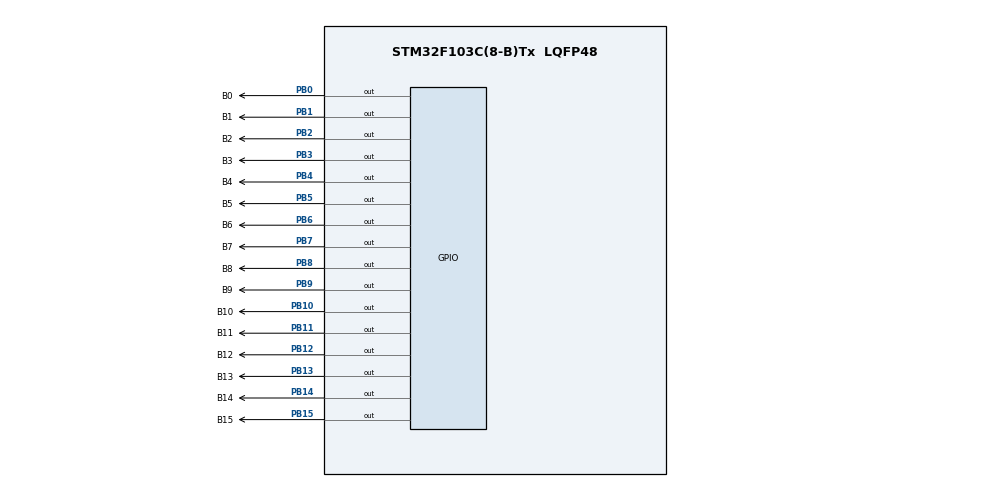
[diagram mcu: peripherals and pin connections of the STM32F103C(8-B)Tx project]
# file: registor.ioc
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Mcu.Family=STM32F1
Mcu.Name=STM32F103C(8-B)Tx
Mcu.Package=LQFP48
NVIC.PriorityGroup=NVIC_PRIORITYGROUP_4
PB0.GPIO_Label=B0
PB0.Signal=GPIO_Output
PB1.GPIO_Label=B1
PB1.Signal=GPIO_Output
PB10.GPIO_Label=B10
PB10.Signal=GPIO_Output
PB11.GPIO_Label=B11
PB11.Signal=GPIO_Output
PB12.GPIO_Label=B12
PB12.Signal=GPIO_Output
PB13.GPIO_Label=B13
PB13.Signal=GPIO_Output
PB14.GPIO_Label=B14
PB14.Signal=GPIO_Output
PB15.GPIO_Label=B15
PB15.Signal=GPIO_Output
PB2.GPIO_Label=B2
PB2.Signal=GPIO_Output
PB3.GPIO_Label=B3
PB3.Signal=GPIO_Output
PB4.GPIO_Label=B4
PB4.Signal=GPIO_Output
PB5.GPIO_Label=B5
PB5.Signal=GPIO_Output
PB6.GPIO_Label=B6
PB6.Signal=GPIO_Output
PB7.GPIO_Label=B7
PB7.Signal=GPIO_Output
PB8.GPIO_Label=B8
PB8.Signal=GPIO_Output
PB9.GPIO_Label=B9
PB9.Signal=GPIO_Output
PD0-OSC_IN.Mode=HSE-External-Oscillator
PD0-OSC_IN.Signal=RCC_OSC_IN
PD1-OSC_OUT.Mode=HSE-External-Oscillator
PD1-OSC_OUT.Signal=RCC_OSC_OUT
ProjectManager.HeapSize=0x200
ProjectManager.StackSize=0x400
ProjectManager.TargetToolchain=STM32CubeIDE
RCC.APB1Freq_Value=8000000
RCC.APB2Freq_Value=8000000
VP_SYS_VS_ND.Mode=No_Debug
board=custom

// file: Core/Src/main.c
/* USER CODE BEGIN Header */
/**
  ******************************************************************************
  * @file           : main.c
  * @brief          : Main program body
  ******************************************************************************
  * @attention
  *
  * Copyright (c) 2023 STMicroelectronics.
  * All rights reserved.
  *
  * This software is licensed under terms that can be found in the LICENSE file
  * in the root directory of this software component.
  * If no LICENSE file comes with this software, it is provided AS-IS.
  *
  ******************************************************************************
  */
/* USER CODE END Header */
#include "main.h"

void SystemClock_Config(void);
static void MX_GPIO_Init(void);

/* USER CODE BEGIN 0 */
uint32_t a;

/* USER CODE END 0 */

int main(void)
{

  /* MCU Configuration--------------------------------------------------------*/

  /* Reset of all peripherals, Initializes the Flash interface and the Systick. */
  HAL_Init();

  /* Configure the system clock */
  SystemClock_Config();

  /* Initialize all configured peripherals */
  MX_GPIO_Init();
  /* USER CODE BEGIN 2 */

   //ACTIVO EL CONTADOR PARA DEBBUGER
      CoreDebug->DEMCR |= CoreDebug_DEMCR_TRCENA_Msk;
       DWT->CTRL |= DWT_CTRL_CYCCNTENA_Msk;

  /* USER CODE END 2 */

  /* Infinite loop */
  /* USER CODE BEGIN WHILE */

   GPIOB->ODR=0x0f0f;
   HAL_Delay(1000);

   while (1)
  {  // encender un led

       DWT->CYCCNT=0;  //LIMPI EL CONTADOR
     //  HAL_GPIO_TogglePin(B5_GPIO_Port, B5_Pin);// 46 cicLo
      // HAL_Delay(200);

/*
       //afectando otros bit
         DWT->CYCCNT=0;  //LIMPI EL CONTADOR
         GPIOB->ODR=1<<5; // 4 CICLO
         HAL_Delay(100);
         DWT->CYCCNT=0;  //LIMPI EL CONTADOR
         B5_GPIO_Port->ODR=0;    //4 CICLO
         HAL_Delay(100);
*/

/*
       //afectando otros bit
       DWT->CYCCNT=0;  //LIMPI EL CONTADOR
       B5_GPIO_Port->ODR=B5_Pin; // 4 CICLO
       HAL_Delay(100);
       B5_GPIO_Port->ODR=0;    //4 CICLO
       HAL_Delay(100);
*/

/*
    //sin afectar otro bit usando xor
      DWT->CYCCNT=0;
       GPIOB->ODR= GPIOB->ODR ^ B5_Pin; // 11 CICLO
      HAL_Delay(200);
    // GPIOB->ODR^=B5_Pin;  // 11 CICLOS
*/

/*
   	 //SIN AFECTAR otro bit forma atomica

        DWT->CYCCNT=0;  //LIMPI EL CONTADOR
          GPIOB->BSRR=B5_Pin;
           HAL_Delay(100);
           DWT->CYCCNT=0;  //LIMPI EL CONTADOR
           B5_GPIO_Port->BRR=B5_Pin;
           HAL_Delay(100);
*/

    /*   // FORMA ATOMICA USANDO SOLO REGISTRO BSRR
	      GPIOB->BSRR=B5_Pin;//coloca 1
	      //GPIOB->BSRR=1<<5;
		  HAL_Delay(100);
		  GPIOB->BSRR=B5_Pin<<16;//COLOCA EL CERO
		  //  GPIOB->BSRR=1<<(16+5);//  si va a coloca cero lo desplaza 16 veces + el bit deseasdo
		  HAL_Delay(100);
*/

//  COLOCAR UN BIT ESPECIFICO EN UNO  (15)

		  //MODO ATOMICO
	 // B15_GPIO_Port->BSRR=B15_Pin;

		   //NO ATOMICO

		  //B15_GPIO_Port->ODR |=B15_Pin;
	//	  GPIOB->ODR |=1<<15;

         //colocar un bit en cero  (11)
		   //MODO ATOMICO
//			B11_GPIO_Port->BRR=B11_Pin;

		  //no atpmica
		//   GPIOB->ODR &=~(1<<11);

		  //INVERTIR UN BIT (14)
		  //GPIOB->ODR ^=1<<14;

       // CARGA DE UN DATO FORMA ATOMICA
          a=0B10101010101010101;
          DWT->CYCCNT=0;  //LIMPI EL CONTADOR
          GPIOB->BSRR=a|(~a<<16);///14 ciclos cargar un dato de forma atomica
         // DWT->CYCCNT=0;  //LIMPI EL CONTADOR

    /* USER CODE END WHILE */

  }
}

void SystemClock_Config(void)
{
  RCC_OscInitTypeDef RCC_OscInitStruct = {0};
  RCC_ClkInitTypeDef RCC_ClkInitStruct = {0};

  /** Initializes the RCC Oscillators according to the specified parameters
  * in the RCC_OscInitTypeDef structure.
  */
  RCC_OscInitStruct.OscillatorType = RCC_OSCILLATORTYPE_HSI;
  RCC_OscInitStruct.HSIState = RCC_HSI_ON;
  RCC_OscInitStruct.HSICalibrationValue = RCC_HSICALIBRATION_DEFAULT;
  RCC_OscInitStruct.PLL.PLLState = RCC_PLL_NONE;
  if (HAL_RCC_OscConfig(&RCC_OscInitStruct) != HAL_OK)
  {
    Error_Handler();
  }

  /** Initializes the CPU, AHB and APB buses clocks
  */
  RCC_ClkInitStruct.ClockType = RCC_CLOCKTYPE_HCLK|RCC_CLOCKTYPE_SYSCLK
                              |RCC_CLOCKTYPE_PCLK1|RCC_CLOCKTYPE_PCLK2;
  RCC_ClkInitStruct.SYSCLKSource = RCC_SYSCLKSOURCE_HSI;
  RCC_ClkInitStruct.AHBCLKDivider = RCC_SYSCLK_DIV1;
  RCC_ClkInitStruct.APB1CLKDivider = RCC_HCLK_DIV1;
  RCC_ClkInitStruct.APB2CLKDivider = RCC_HCLK_DIV1;

  if (HAL_RCC_ClockConfig(&RCC_ClkInitStruct, FLASH_LATENCY_0) != HAL_OK)
  {
    Error_Handler();
  }
}

static void MX_GPIO_Init(void)
{
  GPIO_InitTypeDef GPIO_InitStruct = {0};

  /* GPIO Ports Clock Enable */
  __HAL_RCC_GPIOD_CLK_ENABLE();
  __HAL_RCC_GPIOB_CLK_ENABLE();

  /*Configure GPIO pin Output Level */
  HAL_GPIO_WritePin(GPIOB, B0_Pin|B1_Pin|B2_Pin|B10_Pin
                          |B11_Pin|B12_Pin|B13_Pin|B14_Pin
                          |B15_Pin|B3_Pin|B4_Pin|B5_Pin
                          |B6_Pin|B7_Pin|B8_Pin|B9_Pin, GPIO_PIN_RESET);

  /*Configure GPIO pins : B0_Pin B1_Pin B2_Pin B10_Pin
                           B11_Pin B12_Pin B13_Pin B14_Pin
                           B15_Pin B3_Pin B4_Pin B5_Pin
                           B6_Pin B7_Pin B8_Pin B9_Pin */
  GPIO_InitStruct.Pin = B0_Pin|B1_Pin|B2_Pin|B10_Pin
                          |B11_Pin|B12_Pin|B13_Pin|B14_Pin
                          |B15_Pin|B3_Pin|B4_Pin|B5_Pin
                          |B6_Pin|B7_Pin|B8_Pin|B9_Pin;
  GPIO_InitStruct.Mode = GPIO_MODE_OUTPUT_PP;
  GPIO_InitStruct.Pull = GPIO_NOPULL;
  GPIO_InitStruct.Speed = GPIO_SPEED_FREQ_LOW;
  HAL_GPIO_Init(GPIOB, &GPIO_InitStruct);

}

void Error_Handler(void)
{
  __disable_irq();
  while (1)
  {
  }
}
